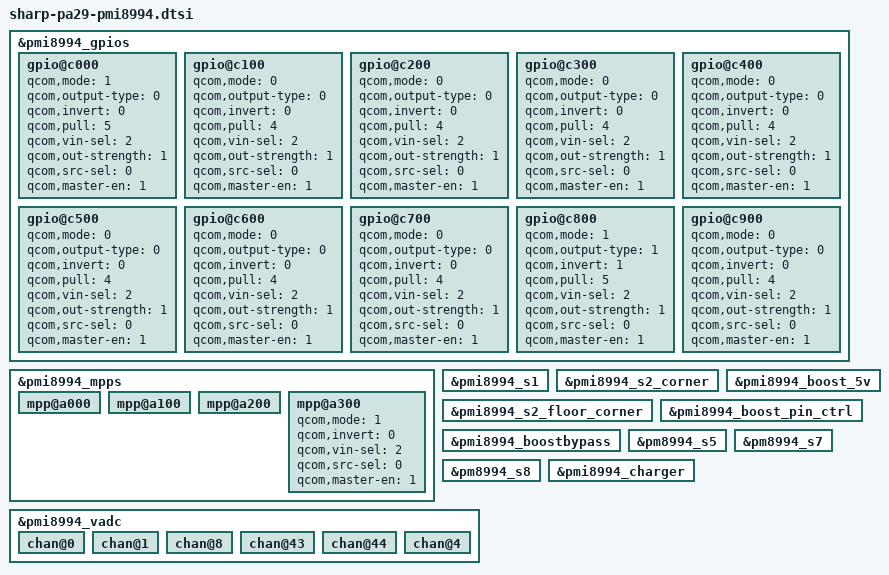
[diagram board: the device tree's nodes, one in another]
/* Copyright (c) 2014, The Linux Foundation. All rights reserved.
 *
 * This program is free software; you can redistribute it and/or modify
 * it under the terms of the GNU General Public License version 2 and
 * only version 2 as published by the Free Software Foundation.
 *
 * This program is distributed in the hope that it will be useful,
 * but WITHOUT ANY WARRANTY; without even the implied warranty of
 * MERCHANTABILITY or FITNESS FOR A PARTICULAR PURPOSE.  See the
 * GNU General Public License for more details.
 */

#include "sharp-pa29-chg-param.dtsi"

/*****************************************/
/*  pmi8994-gpios: qpnp-pin               */
/*****************************************/

&pmi8994_gpios {

	gpio@c000 { /* GPIO_01 */
		/* VFEL_RST */
		qcom,mode = <1>;		/* DIG_OUT */
		qcom,output-type = <0>;		/* CMOS */
		qcom,invert = <0>;		/* DISABLE */
		qcom,pull = <5>;		/* NO_PULL */
		qcom,vin-sel = <2>;		/* S4 */
		qcom,out-strength = <1>;	/* LOW */
		qcom,src-sel = <0>;		/* CONSTANT */
		qcom,master-en = <1>;		/* ENSABLE */
	};

	gpio@c100 { /* GPIO_02 */
		/* Unused */
		qcom,mode = <0>;		/* DIG_IN */
		qcom,output-type = <0>;		/* CMOS */
		qcom,invert = <0>;		/* DISABLE */
		qcom,pull = <4>;		/* PULL_DN */
		qcom,vin-sel = <2>;		/* S4 */
		qcom,out-strength = <1>;	/* LOW */
		qcom,src-sel = <0>;		/* CONSTANT */
		qcom,master-en = <1>;		/* ENSABLE */
	};

	gpio@c200 { /* GPIO_03 */
		/* Unused */
		qcom,mode = <0>;		/* DIG_IN */
		qcom,output-type = <0>;		/* CMOS */
		qcom,invert = <0>;		/* DISABLE */
		qcom,pull = <4>;		/* PULL_DN */
		qcom,vin-sel = <2>;		/* S4 */
		qcom,out-strength = <1>;	/* LOW */
		qcom,src-sel = <0>;		/* CONSTANT */
		qcom,master-en = <1>;		/* ENSABLE */
	};

	gpio@c300 { /* GPIO_04 */
		/* Unused */
		qcom,mode = <0>;		/* DIG_IN */
		qcom,output-type = <0>;		/* CMOS */
		qcom,invert = <0>;		/* DISABLE */
		qcom,pull = <4>;		/* PULL_DN */
		qcom,vin-sel = <2>;		/* S4 */
		qcom,out-strength = <1>;	/* LOW */
		qcom,src-sel = <0>;		/* CONSTANT */
		qcom,master-en = <1>;		/* ENSABLE */
	};

	gpio@c400 { /* GPIO_05 */
		/* Unused */
		qcom,mode = <0>;		/* DIG_IN */
		qcom,output-type = <0>;		/* CMOS */
		qcom,invert = <0>;		/* DISABLE */
		qcom,pull = <4>;		/* PULL_DN */
		qcom,vin-sel = <2>;		/* S4 */
		qcom,out-strength = <1>;	/* LOW */
		qcom,src-sel = <0>;		/* CONSTANT */
		qcom,master-en = <1>;		/* ENSABLE */
	};

	gpio@c500 { /* GPIO_06 */
		/* Unused */
		qcom,mode = <0>;		/* DIG_IN */
		qcom,output-type = <0>;		/* CMOS */
		qcom,invert = <0>;		/* DISABLE */
		qcom,pull = <4>;		/* PULL_DN */
		qcom,vin-sel = <2>;		/* S4 */
		qcom,out-strength = <1>;	/* LOW */
		qcom,src-sel = <0>;		/* CONSTANT */
		qcom,master-en = <1>;		/* ENSABLE */
	};

	gpio@c600 { /* GPIO_07 */
		/* Unused */
		qcom,mode = <0>;		/* DIG_IN */
		qcom,output-type = <0>;		/* CMOS */
		qcom,invert = <0>;		/* DISABLE */
		qcom,pull = <4>;		/* PULL_DN */
		qcom,vin-sel = <2>;		/* S4 */
		qcom,out-strength = <1>;	/* LOW */
		qcom,src-sel = <0>;		/* CONSTANT */
		qcom,master-en = <1>;		/* ENSABLE */
	};

	gpio@c700 { /* GPIO_08 */
		/* Unused */
		qcom,mode = <0>;		/* DIG_IN */
		qcom,output-type = <0>;		/* CMOS */
		qcom,invert = <0>;		/* DISABLE */
		qcom,pull = <4>;		/* PULL_DN */
		qcom,vin-sel = <2>;		/* S4 */
		qcom,out-strength = <1>;	/* LOW */
		qcom,src-sel = <0>;		/* CONSTANT */
		qcom,master-en = <1>;		/* ENSABLE */
	};

	gpio@c800 { /* GPIO_09 */
		/* TMP_SENSE_PD */
		qcom,mode = <1>;		/* DIG_OUT */
		qcom,output-type = <1>;		/* NMOS */
		qcom,invert = <1>;		/* ENABLE */
		qcom,pull = <5>;		/* NO_PULL */
		qcom,vin-sel = <2>;		/* S4 */
		qcom,out-strength = <1>;	/* LOW */
		qcom,src-sel = <0>;		/* CONSTANT */
		qcom,master-en = <1>;		/* ENSABLE */
	};

	gpio@c900 { /* GPIO_10 */
		/* Unused */
		qcom,mode = <0>;		/* DIG_IN */
		qcom,output-type = <0>;		/* CMOS */
		qcom,invert = <0>;		/* DISABLE */
		qcom,pull = <4>;		/* PULL_DN */
		qcom,vin-sel = <2>;		/* S4 */
		qcom,out-strength = <1>;	/* LOW */
		qcom,src-sel = <0>;		/* CONSTANT */
		qcom,master-en = <1>;		/* ENSABLE */
	};
};
/*****************************************/
/*  pmi8994-mpps: qpnp-pin                */
/*****************************************/

&pmi8994_mpps {

	mpp@a000 { /* MPP_01 */
		/* VBAT_MONITOR */
//		qcom,mode = <0>;		/* DIG_IN */
//		qcom,invert = <0>;		/* DISABLE */
//		qcom,src-sel = <0>;		/* CONSTANT */
//		qcom,master-en = <1>;	/* ENSABLE */

	};

	mpp@a100 { /* MPP_02 */
	};

	mpp@a200 { /* MPP_03 */
	};

	mpp@a300 { /* MPP_04 */
		/* Unused */
		qcom,mode = <1>;		/* DIG_OUT */
		qcom,invert = <0>;		/* DISABLE */
		qcom,vin-sel = <2>;		/* S4 */
		qcom,src-sel = <0>;		/* CONSTANT */
		qcom,master-en = <1>;		/* ENSABLE */

	};
};
/*****************************************/
/*  pmi8994: rpm-regulator                */
/*****************************************/
&pmi8994_s1 { /* pmi8994_s1 */
};

&pmi8994_s2_corner { /* pmi8994_s2_corner */
};

&pmi8994_s2_floor_corner { /* pmi8994_s2_floor_corner */
};

&pmi8994_boost_5v { /* pmi8994_boost_5v: */
};

&pmi8994_boost_pin_ctrl { /* pmi8994_boost_pin_ctrl: */
};

&pmi8994_boostbypass { /* pmi8994_boostbypass */
};

&pm8994_s5 { /* 8994_s5 */
};

&pm8994_s7 { /* 8994_s7 */
};
/* PM8994 S8 = VDD_APC0 supply */
&pm8994_s8 { /* 8994_s8 */
};

/*****************************************/
/*  qpnp-adc-voltage                     */
/*****************************************/

&pmi8994_vadc {
	chan@0 { /* usbin */
	};

	chan@1 { /* dcin */
	};
	
	chan@8 { /* die_temp */
	};
	
	chan@43 { /* usb_dp */
	};

	chan@44 { /* usb_dm */
	};

	chan@4 { /* usb_id */
	};
};

/*****************************************/
/*  pmi8994_charger                     */
/*****************************************/
&pmi8994_charger {
};
